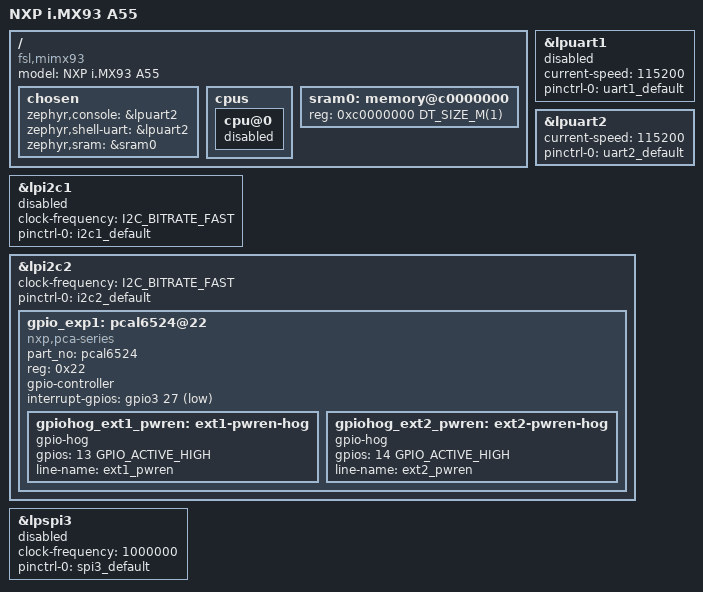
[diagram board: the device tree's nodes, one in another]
/*
 * Copyright 2022 NXP
 *
 * SPDX-License-Identifier: Apache-2.0
 */

/dts-v1/;

#include <nxp/nxp_mimx93_a55.dtsi>
#include "mimx93_evk-pinctrl.dtsi"

/ {
	model = "NXP i.MX93 A55";
	compatible = "fsl,mimx93";

	chosen {
		zephyr,console = &lpuart2;
		zephyr,shell-uart = &lpuart2;
		zephyr,sram = &sram0;
	};

	cpus {
		cpu@0 {
			status = "disabled";
		};
	};

	sram0: memory@c0000000 {
		reg = <0xc0000000 DT_SIZE_M(1)>;
	};
};

&lpuart1 {
	status = "disabled";
	current-speed = <115200>;
	/* clocks = <&ccm IMX_CCM_UART4_CLK 0x6c 24>; */
	pinctrl-0 = <&uart1_default>;
	pinctrl-names = "default";
};

&lpuart2 {
	status = "okay";
	current-speed = <115200>;
	/* clocks = <&ccm IMX_CCM_UART4_CLK 0x6c 24>; */
	pinctrl-0 = <&uart2_default>;
	pinctrl-names = "default";
};


&lpi2c1{
	status = "disabled";
	clock-frequency = <I2C_BITRATE_FAST>;
	pinctrl-0 = <&i2c1_default>;
	pinctrl-names = "default";
};

&lpi2c2 {
	status = "okay";
	clock-frequency = <I2C_BITRATE_FAST>;
	pinctrl-0 = <&i2c2_default>;
	pinctrl-names = "default";

	gpio_exp1: pcal6524@22 {
		compatible = "nxp,pca-series";
        part_no = "pcal6524";
		reg = <0x22>;
		gpio-controller;
		#gpio-cells = <2>;
        interrupt-gpios = <&gpio3 27 (GPIO_ACTIVE_LOW|GPIO_PULL_UP)>;
        status = "okay";

		/** M.2 power en */
        gpiohog_ext1_pwren: ext1-pwren-hog {
            gpio-hog;
            gpios = <13 GPIO_ACTIVE_HIGH>;
            line-name = "ext1_pwren";
        };

		/** LVDS backlight en */
		gpiohog_ext2_pwren: ext2-pwren-hog {
            gpio-hog;
            gpios = <14 GPIO_ACTIVE_HIGH>;
            line-name = "ext2_pwren";
        };
    };
};

&lpspi3 {
	status = "disabled";
	clock-frequency = <1000000>;
	pinctrl-0 = <&spi3_default>;
	pinctrl-names = "default";
};
